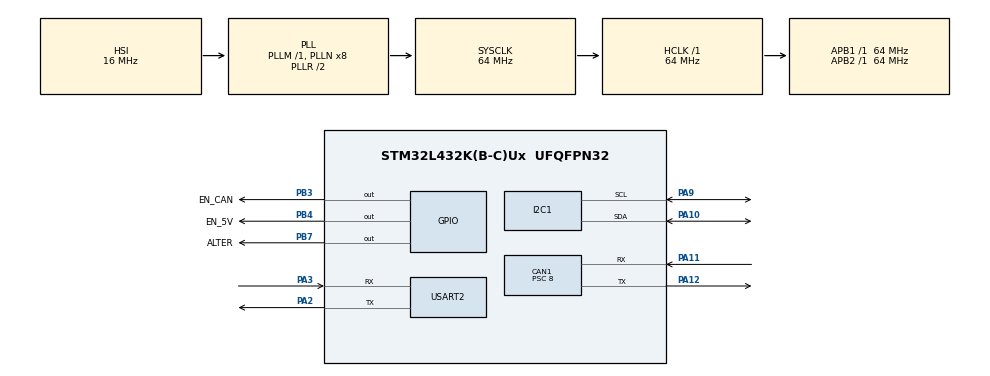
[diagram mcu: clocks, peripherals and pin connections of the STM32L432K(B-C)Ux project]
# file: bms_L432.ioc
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CAN1.ABOM=ENABLE
CAN1.AWUM=ENABLE
CAN1.BS1=CAN_BS1_6TQ
CAN1.CalculateBaudRate=1000000
CAN1.CalculateTimeBit=1000
CAN1.CalculateTimeQuantum=125.0
CAN1.NART=ENABLE
CAN1.Prescaler=8
CAN1.TTCM=DISABLE
CAN1.TXFP=ENABLE
I2C1.I2C_Fall_Time=5
I2C1.I2C_Rise_Time=5
I2C1.Timing=0x10807DBB
Mcu.Family=STM32L4
Mcu.Name=STM32L432K(B-C)Ux
Mcu.Package=UFQFPN32
NVIC.CAN1_RX0_IRQn=true\:0\:0\:false\:false\:true\:true\:true\:true
NVIC.PriorityGroup=NVIC_PRIORITYGROUP_4
NVIC.USART2_IRQn=true\:0\:0\:false\:false\:true\:true\:true\:true
PA10.Mode=I2C
PA10.Signal=I2C1_SDA
PA11.Mode=CAN_Activate
PA11.Signal=CAN1_RX
PA12.Mode=CAN_Activate
PA12.Signal=CAN1_TX
PA13\ (JTMS-SWDIO).Mode=Serial_Wire
PA13\ (JTMS-SWDIO).Signal=SYS_JTMS-SWDIO
PA14\ (JTCK-SWCLK).Mode=Serial_Wire
PA14\ (JTCK-SWCLK).Signal=SYS_JTCK-SWCLK
PA2.Mode=Asynchronous
PA2.Signal=USART2_TX
PA3.Mode=Asynchronous
PA3.Signal=USART2_RX
PA9.Mode=I2C
PA9.Signal=I2C1_SCL
PB3\ (JTDO-TRACESWO).GPIO_Label=EN_CAN
PB3\ (JTDO-TRACESWO).Signal=GPIO_Output
PB4\ (NJTRST).GPIO_Label=EN_5V
PB4\ (NJTRST).Signal=GPIO_Output
PB7.GPIO_Label=ALTER
PB7.Signal=GPIO_Output
ProjectManager.HeapSize=0x200
ProjectManager.StackSize=0x400
ProjectManager.TargetToolchain=STM32CubeIDE
RCC.ADCFreq_Value=64000000
RCC.AHBFreq_Value=64000000
RCC.APB1Freq_Value=64000000
RCC.APB1TimFreq_Value=64000000
RCC.APB2Freq_Value=64000000
RCC.APB2TimFreq_Value=64000000
RCC.CortexFreq_Value=64000000
RCC.HCLKFreq_Value=64000000
RCC.HSE_VALUE=8000000
RCC.HSI48_VALUE=48000000
RCC.HSI_VALUE=16000000
RCC.LSE_VALUE=32768
RCC.MSIClockRange=RCC_MSIRANGE_8
RCC.MSI_VALUE=16000000
RCC.PLLSourceVirtual=RCC_PLLSOURCE_HSI
RCC.SYSCLKFreq_VALUE=64000000
RCC.SYSCLKSource=RCC_SYSCLKSOURCE_PLLCLK
RCC.USBFreq_Value=64000000
RCC.VCOOutputFreq_Value=128000000
USART2.OverSampling=UART_OVERSAMPLING_8
USART2.VirtualMode-Asynchronous=VM_ASYNC
board=custom

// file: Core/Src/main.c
/* USER CODE BEGIN Header */
/**
 ******************************************************************************
 * @file           : main.c
 * @brief          : Main program body
 ******************************************************************************
 * @attention
 *
 * Copyright (c) 2024 STMicroelectronics.
 * All rights reserved.
 *
 * This software is licensed under terms that can be found in the LICENSE file
 * in the root directory of this software component.
 * If no LICENSE file comes with this software, it is provided AS-IS.
 *
 ******************************************************************************
 */
/* USER CODE END Header */
#include "main.h"
#include "can.h"
#include "gpio.h"
#include "i2c.h"
#include "usart.h"

/* USER CODE BEGIN Includes */
#include "utils/bms.h"
/* USER CODE END Includes */

void SystemClock_Config(void);

int main(void)
{

    /* USER CODE BEGIN 1 */
    /*
     if(HAL_FLASH_Unlock() == HAL_OK)
        {
            if(HAL_FLASH_OB_Unlock() == HAL_OK)
            {
                // Instructions found in section 5.4.2 of rm0440 STM32G4 Series manual
                FLASH->OPTR &= ~(1<<(26)); // clear nSWBOOT0 bit
                FLASH->PCROP1SR |= (1<<16);  // set BOOT_LOCK bit
                FLASH->CR |= (1<<17);       // set options start bit OPTSTRT
                while((FLASH->SR & (1<<16))); // wait for the bsy bit to be cleared
                HAL_FLASH_OB_Lock();
                HAL_FLASH_OB_Launch();

            }
            HAL_FLASH_Lock();
        }
        */
    /* USER CODE END 1 */

    /* MCU Configuration--------------------------------------------------------*/

    /* Reset of all peripherals, Initializes the Flash interface and the Systick. */
    HAL_Init();

    /* Configure the system clock */
    SystemClock_Config();

    /* Initialize all configured peripherals */
    MX_GPIO_Init();
    MX_CAN1_Init();
    MX_I2C1_Init();
    MX_USART2_UART_Init();
    /* USER CODE BEGIN 2 */
    bms_init();
    /* USER CODE END 2 */

    /* Infinite loop */
    /* USER CODE BEGIN WHILE */
    bms();
    while(1)
    {
        /* USER CODE END WHILE */

    }
}

void SystemClock_Config(void)
{
    RCC_OscInitTypeDef RCC_OscInitStruct = {0};
    RCC_ClkInitTypeDef RCC_ClkInitStruct = {0};

    /** Configure the main internal regulator output voltage
     */
    if(HAL_PWREx_ControlVoltageScaling(PWR_REGULATOR_VOLTAGE_SCALE1) != HAL_OK)
    {
        Error_Handler();
    }

    /** Initializes the RCC Oscillators according to the specified parameters
     * in the RCC_OscInitTypeDef structure.
     */
    RCC_OscInitStruct.OscillatorType = RCC_OSCILLATORTYPE_HSI;
    RCC_OscInitStruct.HSIState = RCC_HSI_ON;
    RCC_OscInitStruct.HSICalibrationValue = RCC_HSICALIBRATION_DEFAULT;
    RCC_OscInitStruct.PLL.PLLState = RCC_PLL_ON;
    RCC_OscInitStruct.PLL.PLLSource = RCC_PLLSOURCE_HSI;
    RCC_OscInitStruct.PLL.PLLM = 1;
    RCC_OscInitStruct.PLL.PLLN = 8;
    RCC_OscInitStruct.PLL.PLLP = RCC_PLLP_DIV7;
    RCC_OscInitStruct.PLL.PLLQ = RCC_PLLQ_DIV2;
    RCC_OscInitStruct.PLL.PLLR = RCC_PLLR_DIV2;
    if(HAL_RCC_OscConfig(&RCC_OscInitStruct) != HAL_OK)
    {
        Error_Handler();
    }

    /** Initializes the CPU, AHB and APB buses clocks
     */
    RCC_ClkInitStruct.ClockType = RCC_CLOCKTYPE_HCLK | RCC_CLOCKTYPE_SYSCLK | RCC_CLOCKTYPE_PCLK1 | RCC_CLOCKTYPE_PCLK2;
    RCC_ClkInitStruct.SYSCLKSource = RCC_SYSCLKSOURCE_PLLCLK;
    RCC_ClkInitStruct.AHBCLKDivider = RCC_SYSCLK_DIV1;
    RCC_ClkInitStruct.APB1CLKDivider = RCC_HCLK_DIV1;
    RCC_ClkInitStruct.APB2CLKDivider = RCC_HCLK_DIV1;

    if(HAL_RCC_ClockConfig(&RCC_ClkInitStruct, FLASH_LATENCY_3) != HAL_OK)
    {
        Error_Handler();
    }
}

void Error_Handler(void)
{
    __disable_irq();
    while(1)
    {
    }
}
